VERSION ""

NS_ :

BS_:

BU_:

BO_ 2 VC_ThrottleBrake: 3 Vector__XXX
 SG_ Brake_pressed : 16|1@1+ (1,0) [0|0] "" Vector__XXX
 SG_ Throttle : 0|16@1+ (1,0) [0|0] "" Vector__XXX

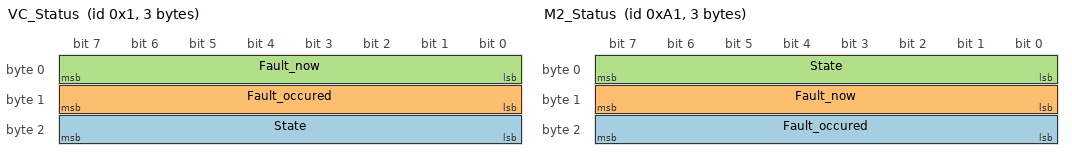
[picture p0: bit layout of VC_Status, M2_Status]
BO_ 1 VC_Status: 3 Vector__XXX
 SG_ State : 16|8@1+ (1,0) [0|0] "" Vector__XXX
 SG_ Fault_occured : 8|8@1+ (1,0) [0|0] "" Vector__XXX
 SG_ Fault_now : 0|8@1+ (1,0) [0|0] "" Vector__XXX

BO_ 161 M2_Status: 3 Vector__XXX
 SG_ Fault_occured : 16|8@1+ (1,0) [0|0] "" Vector__XXX
 SG_ Fault_now : 8|8@1+ (1,0) [0|0] "" Vector__XXX
 SG_ State : 0|8@1+ (1,0) [0|0] "" Vector__XXX

BO_ 17 M2_BusVoltage: 2 Vector__XXX
 SG_ Vbus : 0|16@1+ (1,0) [0|0] "" Vector__XXX

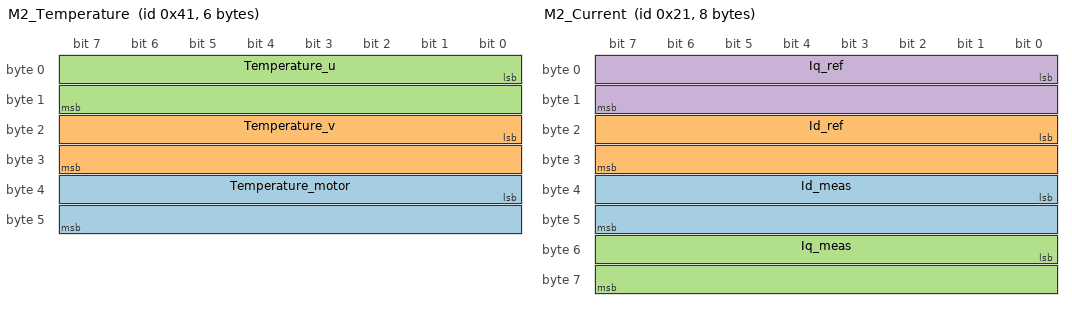
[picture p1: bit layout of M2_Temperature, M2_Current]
BO_ 65 M2_Temperature: 6 Vector__XXX
 SG_ Temperature_motor : 32|16@1- (1,0) [0|0] "" Vector__XXX
 SG_ Temperature_v : 16|16@1- (1,0) [0|0] "" Vector__XXX
 SG_ Temperature_u : 0|16@1- (1,0) [0|0] "" Vector__XXX

BO_ 49 M2_Speed: 8 Vector__XXX
 SG_ Speed_meas : 32|32@1- (1,0) [0|0] "" Vector__XXX
 SG_ Speed_ref : 0|32@1- (1,0) [0|0] "" Vector__XXX

BO_ 33 M2_Current: 8 Vector__XXX
 SG_ Id_meas : 32|16@1- (1,0) [0|0] "" Vector__XXX
 SG_ Id_ref : 16|16@1- (1,0) [0|0] "" Vector__XXX
 SG_ Iq_meas : 48|16@1- (1,0) [0|0] "" Vector__XXX
 SG_ Iq_ref : 0|16@1- (1,0) [0|0] "" Vector__XXX

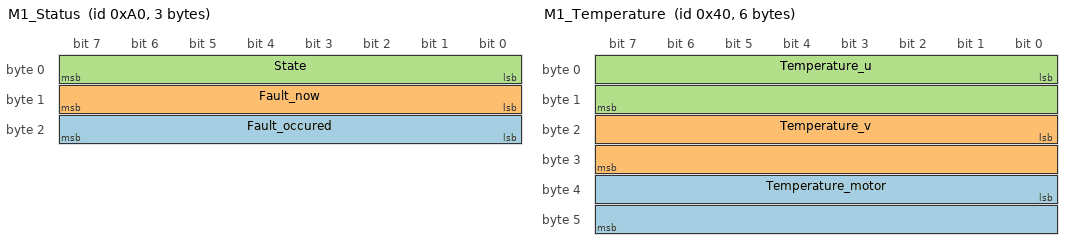
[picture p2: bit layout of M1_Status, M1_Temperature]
BO_ 160 M1_Status: 3 Vector__XXX
 SG_ Fault_occured : 16|8@1+ (1,0) [0|0] "" Vector__XXX
 SG_ Fault_now : 8|8@1+ (1,0) [0|0] "" Vector__XXX
 SG_ State : 0|8@1+ (1,0) [0|0] "" Vector__XXX

BO_ 16 M1_BusVoltage: 2 Vector__XXX
 SG_ Vbus : 0|16@1+ (1,0) [0|0] "" Vector__XXX

BO_ 64 M1_Temperature: 6 Vector__XXX
 SG_ Temperature_motor : 32|16@1- (1,0) [0|0] "" Vector__XXX
 SG_ Temperature_v : 16|16@1- (1,0) [0|0] "" Vector__XXX
 SG_ Temperature_u : 0|16@1- (1,0) [0|0] "" Vector__XXX

BO_ 48 M1_Speed: 8 Vector__XXX
 SG_ Speed_meas : 32|32@1- (1,0) [0|0] "" Vector__XXX
 SG_ Speed_ref : 0|32@1- (1,0) [0|0] "" Vector__XXX

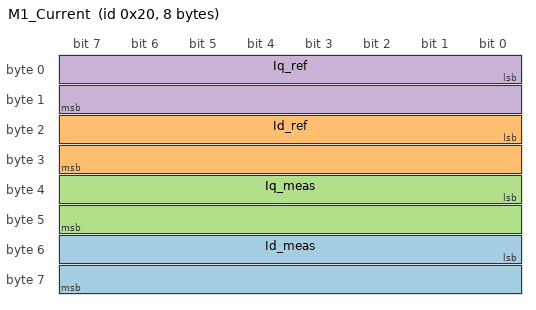
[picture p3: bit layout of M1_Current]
BO_ 32 M1_Current: 8 Vector__XXX
 SG_ Id_meas : 48|16@1- (1,0) [0|0] "" Vector__XXX
 SG_ Id_ref : 16|16@1- (1,0) [0|0] "" Vector__XXX
 SG_ Iq_meas : 32|16@1- (1,0) [0|0] "" Vector__XXX
 SG_ Iq_ref : 0|16@1- (1,0) [0|0] "" Vector__XXX

BA_DEF_  "BusType" STRING ;
BA_DEF_DEF_  "BusType" "CAN";
